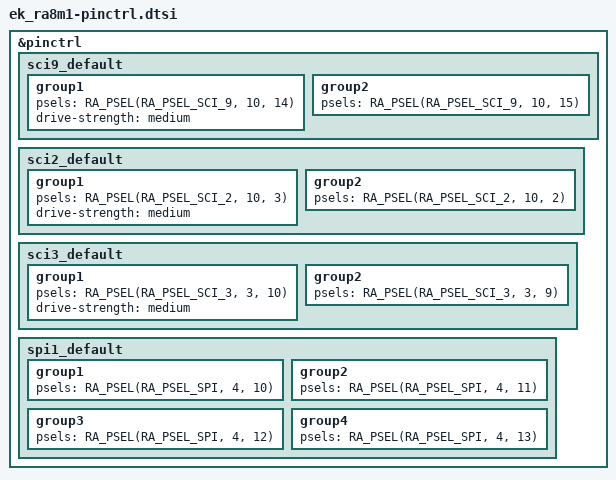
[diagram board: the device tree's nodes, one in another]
/*
 * Copyright (c) 2024 Renesas Electronics Corporation
 * SPDX-License-Identifier: Apache-2.0
 */

&pinctrl {
	sci9_default: sci9_default {
		group1 {
			/* tx */
			psels = <RA_PSEL(RA_PSEL_SCI_9, 10, 14)>;
			drive-strength = "medium";
		};
		group2 {
			/* rx */
			psels = <RA_PSEL(RA_PSEL_SCI_9, 10, 15)>;
		};
	};

	sci2_default: sci2_default {
		group1 {
			/* tx */
			psels = <RA_PSEL(RA_PSEL_SCI_2, 10, 3)>;
			drive-strength = "medium";
		};
		group2 {
			/* rx */
			psels = <RA_PSEL(RA_PSEL_SCI_2, 10, 2)>;
		};
	};

	sci3_default: sci3_default {
		group1 {
			/* tx */
			psels = <RA_PSEL(RA_PSEL_SCI_3, 3, 10)>;
			drive-strength = "medium";
		};
		group2 {
			/* rx */
			psels = <RA_PSEL(RA_PSEL_SCI_3, 3, 9)>;
		};
	};

	sci9_default: sci9_default {
		group1 {
			/* tx */
			psels = <RA_PSEL(RA_PSEL_SCI_9, 10, 14)>;
			drive-strength = "medium";
		};
		group2 {
			/* rx */
			psels = <RA_PSEL(RA_PSEL_SCI_9, 10, 15)>;
		};
	};

	spi1_default: spi1_default {
		group1 {
			/* MISO */
			psels = <RA_PSEL(RA_PSEL_SPI, 4, 10)>;
		};
		group2 {
			/* MOSI */
			psels = <RA_PSEL(RA_PSEL_SPI, 4, 11)>;
		};
		group3 {
			/* RSPCK */
			psels = <RA_PSEL(RA_PSEL_SPI, 4, 12)>;
		};
		group4 {
			/* SSLB */
			psels = <RA_PSEL(RA_PSEL_SPI, 4, 13)>;
		};
	};
};
